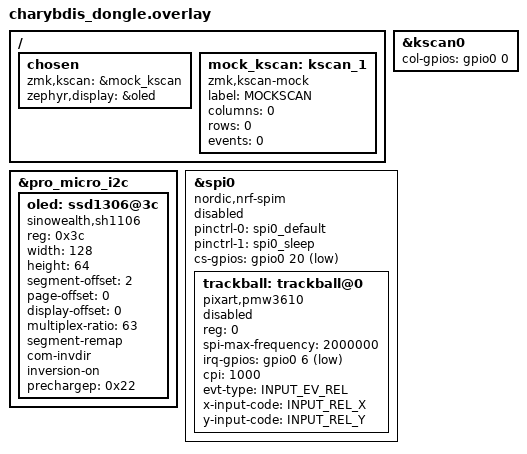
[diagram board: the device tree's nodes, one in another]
#include "charybdis.dtsi"

&kscan0 {
    col-gpios = <&gpio0  0 (GPIO_ACTIVE_HIGH | GPIO_PULL_DOWN)>;
    //row-gpios = <&gpio0  0 (GPIO_ACTIVE_HIGH | GPIO_PULL_DOWN)>;
};

/ {
    chosen {
        zmk,kscan = &mock_kscan;
        zephyr,display = &oled;
    };

    mock_kscan: kscan_1 {
        compatible = "zmk,kscan-mock";
        label = "MOCKSCAN";
        columns = <0>;
        rows = <0>;
        events = <0>;
    };
};

&pro_micro_i2c {
    status = "okay";
    
    oled: ssd1306@3c {
        compatible = "sinowealth,sh1106";
        reg = <0x3c>;
        width = <128>;
        height = <64>;
        segment-offset = <2>;
        page-offset = <0>;
        display-offset = <0>;
        multiplex-ratio = <63>;
        segment-remap;
        com-invdir;
        inversion-on;
        prechargep = <0x22>;
    };
};

&spi0 {
    status = "disabled";
    compatible = "nordic,nrf-spim";
    pinctrl-0 = <&spi0_default>;
    pinctrl-1 = <&spi0_sleep>;
    pinctrl-names = "default", "sleep";
    cs-gpios = <&gpio0 20 GPIO_ACTIVE_LOW>;

    trackball: trackball@0 {
        status = "disabled";
        compatible = "pixart,pmw3610";
        reg = <0>;
        spi-max-frequency = <2000000>;
        irq-gpios = <&gpio0 6 (GPIO_ACTIVE_LOW | GPIO_PULL_UP)>;
        cpi = <1000>;
        evt-type = <INPUT_EV_REL>;
        x-input-code = <INPUT_REL_X>;
        y-input-code = <INPUT_REL_Y>;
    };
};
